# CH569 register map
Vendor: WCH Ltd.; File version: 1.0
Registers are 32-bit, read-write, reset 0x0 unless marked. A register's access mark holds for its fields unless they carry their own. Offsets are from the block's base; [hi:lo] are bit positions; {n}, {i} and the like mark numbered series.

## ECDC
Base 0x40007000
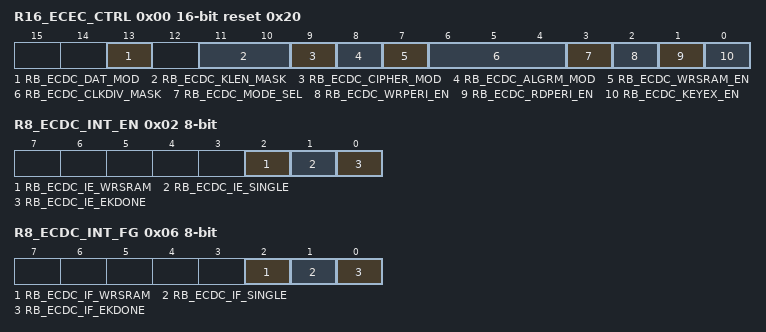
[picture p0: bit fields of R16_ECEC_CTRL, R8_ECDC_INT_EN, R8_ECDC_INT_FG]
0x00 R16_ECEC_CTRL 16-bit reset 0x20 — ECED AES/SM4 register
  [13] RB_ECDC_DAT_MOD — source data and result data is bit endian
  [11:10] RB_ECDC_KLEN_MASK — Key length setting
  [9] RB_ECDC_CIPHER_MOD — Block cipher mode selection
  [8] RB_ECDC_ALGRM_MOD — Encryption and decryption algorithm mode selection
  [7] RB_ECDC_WRSRAM_EN — module dma enable
  [6:4] RB_ECDC_CLKDIV_MASK — Clock divide factor
  [3] RB_ECDC_MODE_SEL — ECDC mode select
  [2] RB_ECDC_WRPERI_EN — when read data from dma
  [1] RB_ECDC_RDPERI_EN — when write data to dma
  [0] RB_ECDC_KEYEX_EN — enable key expansion
0x02 R8_ECDC_INT_EN 8-bit — Interupt enable register
  [2] RB_ECDC_IE_WRSRAM — Memory to memory encryption and decryption completion interrupt enable
  [1] RB_ECDC_IE_SINGLE — Single encryption and decryption completion interrupt enable
  [0] RB_ECDC_IE_EKDONE — Key extension completion interrupt enable
0x06 R8_ECDC_INT_FG 8-bit — Interupt flag register
  [2] RB_ECDC_IF_WRSRAM — Memory to memory encryption and decryption completion interrupt flag
  [1] RB_ECDC_IF_SINGLE — Single encryption and decryption completion interrupt flag
  [0] RB_ECDC_IF_EKDONE — Key extension completion interrupt flag
0x08 R32_ECDC_KEY_255T224 — User key 224-255 register
  [31:0] RB_ECDC_KEY_255T224
0x0C R32_ECDC_KEY_223T192 — User key 192-223 register
  [31:0] RB_ECDC_KEY_223T192
0x10 R32_ECDC_KEY_191T160 — User key 160-191 register
  [31:0] RB_ECDC_KEY_191T160
0x14 R32_ECDC_KEY_159T128 — User key 128-159 register
  [31:0] RB_ECDC_KEY_159T128
0x18 R32_ECDC_KEY_127T96 — User key 96-127 register
  [31:0] RB_ECDC_KEY_127T96
0x1C R32_ECDC_KEY_95T64 — User key 64-95 register
  [31:0] RB_ECDC_KEY_95T64
0x20 R32_ECDC_KEY_63T32 — User key 32-63 register
  [31:0] RB_ECDC_KEY_63T32
0x24 R32_ECDC_KEY_31T0 — User key 0-31 register
  [31:0] RB_ECDC_KEY_31T0
0x28 R32_ECDC_IV_127T96 — CTR mode count 96-127 register
  [31:0] RB_ECDC_IV_127T96
0x2C R32_ECDC_IV_95T64 — CTR mode count 64-95 register
  [31:0] RB_ECDC_IV_95T64
0x30 R32_ECDC_IV_63T32 — CTR mode count 32-63 register
  [31:0] RB_ECDC_IV_63T32
0x34 R32_ECDC_IV_31T0 — CTR mode count 0-31 register
  [31:0] RB_ECDC_IV_31T0
0x40 R32_ECDC_SGSD_127T96 — Single encryption and decryption of original data 96-127 register
  [31:0] RB_ECDC_SGSD_127T96
0x44 R32_ECDC_SGSD_95T64 — Single encryption and decryption of original data 64-95 register
  [31:0] RB_ECDC_SGSD_95T64
0x48 R32_ECDC_SGSD_63T32 — Single encryption and decryption of original data 32-63 register
  [31:0] RB_ECDC_SGSD_63T32
0x4C R32_ECDC_SGSD_31T0 — Single encryption and decryption of original data 0-31 register
  [31:0] RB_ECDC_SGSD_31T0
0x50 R32_ECDC_SGRT_127T96 — Single encryption and decryption result 96-127 register
  [31:0] RB_ECDC_SGRT_127T96
0x54 R32_ECDC_SGRT_95T64 — Single encryption and decryption result 64-95 register
  [31:0] RB_ECDC_SGRT_95T64
0x58 R32_ECDC_SGRT_63T32 — Single encryption and decryption result 0-31 register
  [31:0] RB_ECDC_SGRT_63T32
0x5C RB_ECDC_SGRT_31T0 — Single encryption and decryption result 0-31 register
0x60 R32_ECDC_SRAM_ADDR — encryption and decryption sram start address register
  [16:0] RB_ECDC_SRAM_ADDR
0x64 R32_ECDC_SRAM_LEN — encryption and decryption sram size register
  [16:0] RB_ECDC_SRAM_LEN

## DVP
Base 0x4000E000
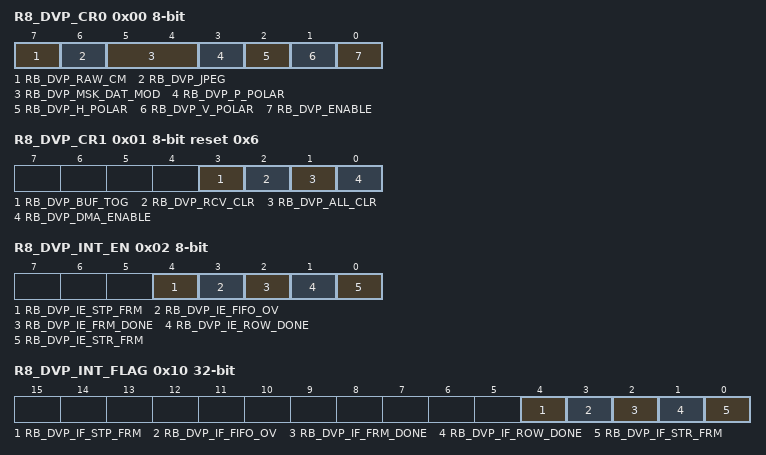
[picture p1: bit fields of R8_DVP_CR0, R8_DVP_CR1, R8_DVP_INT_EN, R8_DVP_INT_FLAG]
0x00 R8_DVP_CR0 8-bit — DVP control register0
  [7] RB_DVP_RAW_CM — DVP row count mode
  [6] RB_DVP_JPEG — DVP JPEG mode
  [5:4] RB_DVP_MSK_DAT_MOD — DVP data bit width confguration
  [3] RB_DVP_P_POLAR — DVP PCLK polarity control
  [2] RB_DVP_H_POLAR — DVP HSYNC polarity control
  [1] RB_DVP_V_POLAR — DVP VSYNC polarity control
  [0] RB_DVP_ENABLE — DVP enable
0x01 R8_DVP_CR1 8-bit reset 0x6 — DVP control register1
  [3] RB_DVP_BUF_TOG — DVP bug toggle by software
  [2] RB_DVP_RCV_CLR — DVP receive logic clear, high action
  [1] RB_DVP_ALL_CLR — DVP all clear, high action
  [0] RB_DVP_DMA_ENABLE — DVP dma enable
0x02 R8_DVP_INT_EN 8-bit — DVP interrupt enable register
  [4] RB_DVP_IE_STP_FRM — DVP frame stop interrupt enable
  [3] RB_DVP_IE_FIFO_OV — DVP receive fifo overflow interrupt enable
  [2] RB_DVP_IE_FRM_DONE — DVP frame received done interrupt enable
  [1] RB_DVP_IE_ROW_DONE — DVP row received done interrupt enable
  [0] RB_DVP_IE_STR_FRM — DVP frame start interrupt enable
0x04 R16_DVP_ROW_NUM 16-bit — DVP row number of a frame indicator register
  [15:0] RB_DVP_ROW_NUM — the number of rows contained in a frame of image data
0x06 R16_DVP_COL_NUM 16-bit — DVP row number of a frame indicator register
  [15:0] RB_DVP_COL_NUM — the number of PCLK cyccles contained in a row of data in RGB mode
0x08 R32_DVP_DMA_BUF0 — DVP dma buffer0 addr
  [16:0] RB_DVP_DMA_BUF0 — the receiving address 0 of DMA
0x0C R32_DVP_DMA_BUF1 — DVP dma buffer1 addr
  [16:0] RB_DVP_DMA_BUF1 — the receiving address1 of DMA
0x10 R8_DVP_INT_FLAG — DVP interrupt flag register
  [4] RB_DVP_IF_STP_FRM — interrupt flag for DVP frame stop
  [3] RB_DVP_IF_FIFO_OV — interrupt flag for DVP receive fifo overflow
  [2] RB_DVP_IF_FRM_DONE — interrupt flag for DVP frame receive done
  [1] RB_DVP_IF_ROW_DONE — interrupt flag for DVP row receive done
  [0] RB_DVP_IF_STR_FRM — interrupt flag for DVP frame start
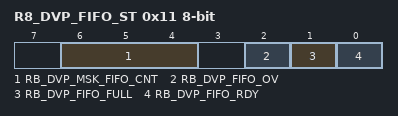
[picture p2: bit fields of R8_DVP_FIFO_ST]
0x11 R8_DVP_FIFO_ST 8-bit ro — DVP receive fifo status
  [6:4] RB_DVP_MSK_FIFO_CNT — DVP receive fifo count
  [2] RB_DVP_FIFO_OV — DVP receive fifo overflow
  [1] RB_DVP_FIFO_FULL — DVP receive fifo full
  [0] RB_DVP_FIFO_RDY — DVP receive fifo ready
0x14 R16_DVP_ROW_CNT 16-bit ro — DVP row count value
  [15:0] RB_DVP_ROW_CNT — DVP receive fifo full
0x16 R16_DVP_COL_CNT 16-bit ro — DVP col count value
  [15:0] RB_DVP_COL_CNT — DVP receive fifo ready

## PFIC — Program Fast Interrupt Controller
Base 0xE000E000
0x00 R32_PFIC_ISR1 ro — Interrupt Status Register
  [31:12] INTSTA — Interrupt ID Status
0x04 R32_PFIC_ISR2 ro — Interrupt Status Register
  [27:0] INTENSTA — Interrupt ID Status
0x20 R32_PFIC_IPR1 ro — Interrupt Pending Register
  [31:12] PENDSTA
0x24 R32_PFIC_IPR2 ro — Interrupt Pending Register
  [27:0] PENDSTA
0x40 R32_PFIC_ITHRESDR — Interrupt Priority Register
  [7:0] THRESHOLD
0x44 R32_PFIC_FIBADDRR — Interrupt Fast Address Register
  [31:28] BASEADDR
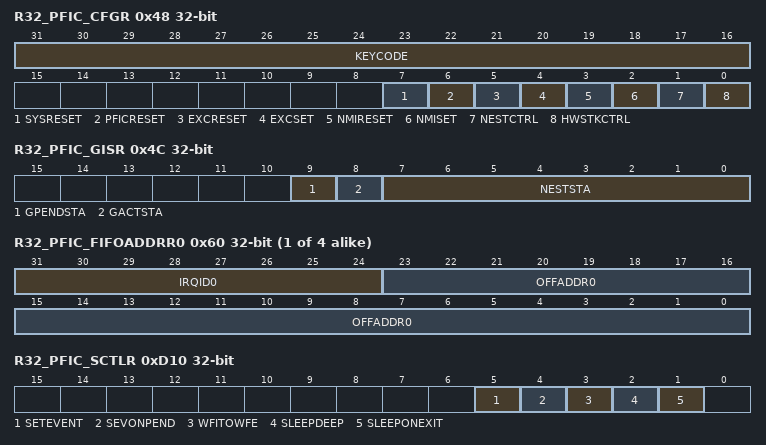
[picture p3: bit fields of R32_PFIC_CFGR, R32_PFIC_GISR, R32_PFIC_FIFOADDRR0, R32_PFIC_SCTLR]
0x48 R32_PFIC_CFGR access per field — Interrupt Config Register
  [31:16] KEYCODE wo
  [7] SYSRESET wo
  [6] PFICRESET wo — PFICRSET
  [5] EXCRESET wo
  [4] EXCSET wo
  [3] NMIRESET wo
  [2] NMISET wo
  [1] NESTCTRL rw
  [0] HWSTKCTRL rw
0x4C R32_PFIC_GISR ro — Interrupt Global Register
  [9] GPENDSTA, [8] GACTSTA, [7:0] NESTSTA
{0x60+4i} R32_PFIC_FIFOADDRR{i} (i=0..3) — Interrupt {i} address Register
  [31:24] IRQID{i}, [23:0] OFFADDR{i}
0x100 R32_PFIC_IENR1 — Interrupt Setting Register
  [31:12] INTEN
0x104 R32_PFIC_IENR2 — Interrupt Setting Register
  [27:0] INTEN
0x180 R32_PFIC_IRER1 — Interrupt Clear Register
  [31:12] INTRESET
0x184 R32_PFIC_IRER2 — Interrupt Clear Register
  [27:0] INTRESET
0x200 R32_PFIC_IPSR1 — Interrupt Pending Register
  [31:12] PENDSET
0x204 R32_PFIC_IPSR2 — Interrupt Pending Register
  [27:0] PENDSET
0x280 R32_PFIC_IPRR1 — Interrupt Pending Clear Register
  [31:12] PENDRESET
0x284 R32_PFIC_IPRR2 — Interrupt Pending Clear Register
  [27:0] PENDRESET
0x300 R32_PFIC_IACTR1 — Interrupt ACTIVE Register
  [31:12] IACTS
0x304 R32_PFIC_IACTR2 — Interrupt ACTIVE Register
  [27:0] IACTS
{0x400+0x20*i} R32_PFIC_IPRIOR{i} (i=0..53) — Interrupt Priority configuration Register
0xAD0 R32_PFIC_IPRIOR54 — Interrupt Priority configuration Register
{0x400+0x20*i} R32_PFIC_IPRIOR{i} (i=55..61) — Interrupt Priority configuration Register
0xBE0 R32_PFIC_IPRIOR62 — Interrupt Priority configuration Register
0xC00 R32_PFIC_IPRIOR63 — Interrupt Priority configuration Register
0xD10 R32_PFIC_SCTLR — System Control Register
  [5] SETEVENT, [4] SEVONPEND, [3] WFITOWFE, [2] SLEEPDEEP, [1] SLEEPONEXIT

## Systick
Base 0xE000F000
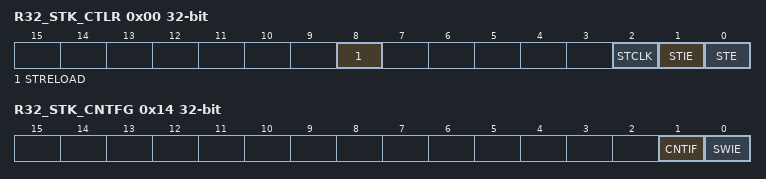
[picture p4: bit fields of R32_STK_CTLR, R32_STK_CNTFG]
0x00 R32_STK_CTLR — Systick counter control register
  [8] STRELOAD — System counter reload control
  [2] STCLK — System counter clock Source selection
  [1] STIE — Systick counter interrupt enable
  [0] STE — Systick counter enable
0x04 R32_STK_CNTL — Systick counter low register
0x08 R32_STK_CNTH — Systick counter high register
0x0C R32_STK_CMPLR — Systick compare low register
  [31:0] CMPL
0x10 R32_STK_CMPHR — Systick compare high register
  [31:0] CMPH
0x14 R32_STK_CNTFG — Systick counter flag
  [1] CNTIF — Systick counter clear zero flag
  [0] SWIE — System soft interrupt enable
